# MM32F3270 register map
File version: 3.01
CPU: CM3 r2p1, selectable endian, MPU, no FPU, 3 interrupt priority bits
Registers are 32-bit, read-write, reset 0x0 unless marked. A register's access mark holds for its fields unless they carry their own. Offsets are from the block's base; [hi:lo] are bit positions; {n}, {i} and the like mark numbered series.

## EXTI — External interrupt/event controller
Base 0x40010400
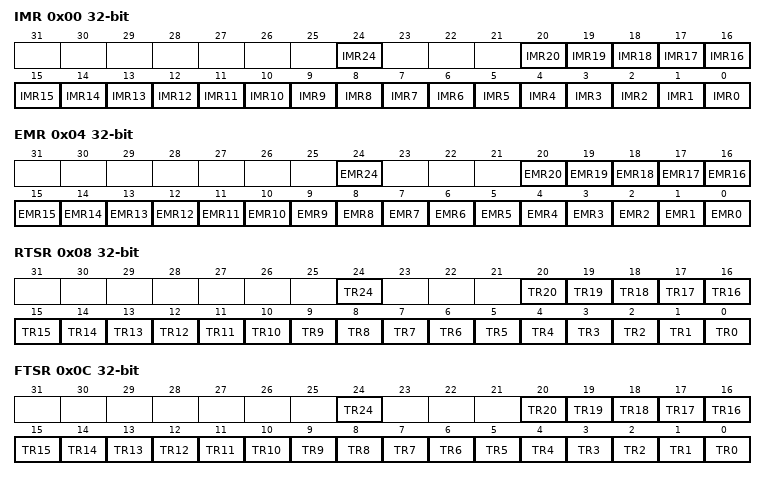
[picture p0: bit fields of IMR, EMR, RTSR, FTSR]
0x00 IMR — Interrupt mask register
  [24] IMR24 — Interrupt Mask on line 24
  [n] IMR{n} (n=0..20) — Interrupt Mask on line {n}
0x04 EMR — Event mask register
  [24] EMR24 — Event Mask on line 24
  [n] EMR{n} (n=0..20) — Event Mask on line {n}
0x08 RTSR — Rising trigger selection register
  [24] TR24 — Rising trigger event configuration bit of line 24
  [n] TR{n} (n=0..20) — Rising trigger event configuration bit of line {n}
0x0C FTSR — Falling trigger selection register
  [24] TR24 — Falling trigger event configuration bit of line 24
  [n] TR{n} (n=0..20) — Falling trigger event configuration bit of line {n}
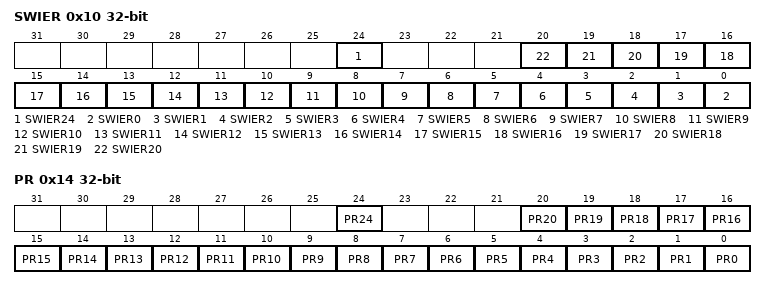
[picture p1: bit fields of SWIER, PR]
0x10 SWIER — Software interrupt event register
  [24] SWIER24 — Software interrupt on line 24
  [n] SWIER{n} (n=0..20) — Software interrupt on line {n}
0x14 PR write-1-clears — Pending register
  [24] PR24 — Pending bit
  [n] PR{n} (n=0..20) — Pending bit

## FLASH
Base 0x40022000
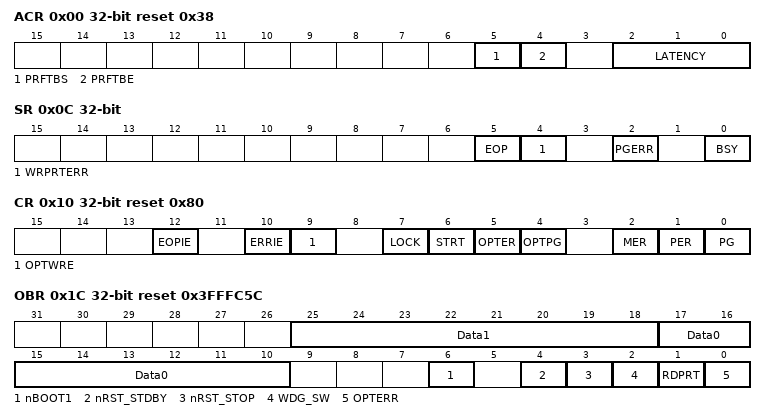
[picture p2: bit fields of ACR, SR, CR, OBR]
0x00 ACR reset 0x38 — Flash access control register
  [5] PRFTBS ro — Prefetch buffer status
  [4] PRFTBE — Prefetch enable
  [2:0] LATENCY
0x04 KEYR wo — Flash key
  [31:0] FKEYR
0x08 OPTKEYR wo — Option byte key
0x0C SR — Flash status register
  [5] EOP write-1-clears — End of operation
  [4] WRPRTERR write-1-clears — Write protection error
  [2] PGERR write-1-clears — Programming error
  [0] BSY ro — Busy
0x10 CR reset 0x80 — Flash control register
  [12] EOPIE — End of operation interrupt enable
  [10] ERRIE — Error interrupt enable
  [9] OPTWRE write-0-clears — Option byte write enable
  [7] LOCK
  [6] STRT — Start
  [5] OPTER — Option byte erase
  [4] OPTPG — Option byte programming
  [2] MER — Mass erase
  [1] PER — Page erase
  [0] PG — Programming
0x14 AR wo — Flash address register
  [31:0] FAR — Flash Address
0x1C OBR ro reset 0x3FFFC5C — Option byte register
  [25:18] Data1
  [17:10] Data0
  [6] nBOOT1
  [4] nRST_STDBY — Standby mode reset
  [3] nRST_STOP — Stop mode reset
  [2] WDG_SW — WDG selection
  [1] RDPRT — Read protection level status
  [0] OPTERR — Option byte error
{0x1C+4i} WRPR{i} ro reset 0xFFFFFFFF (i=1..4) — Write protect register
  [31:0] WRP — Write protect

## GPIOA — General purpose I/O
Base 0x40040000
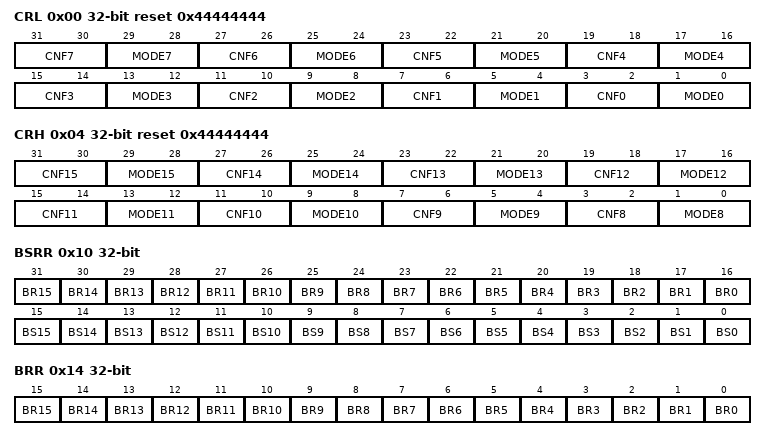
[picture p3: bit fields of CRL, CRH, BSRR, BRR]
0x00 CRL reset 0x44444444 — configuration low register
  [4n+3:4n+2] CNF{n} (n=0..7) — Port {n} configuration bits
  [4n+1:4n] MODE{n} (n=0..7) — Port {n} mode bits
0x04 CRH reset 0x44444444 — configuration high register
  [4n-29:4n-30] CNF{n} (n=8..15) — Port {n} configuration bits
  [4n-31:4n-32] MODE{n} (n=8..15) — Port {n} mode bits
0x08 IDR ro — input data register
  [15:0] IDR — Port input data
0x0C ODR — output data register
  [15:0] ODR — Port output data
0x10 BSRR wo — bit set/reset register
  [n+16] BR{n} (n=0..15) — Port x Reset bit {n}
  [n] BS{n} (n=0..15) — Port x Set bit {n}
0x14 BRR wo — bit reset register
  [n] BR{n} (n=0..15) — Port x Reset bit {n}
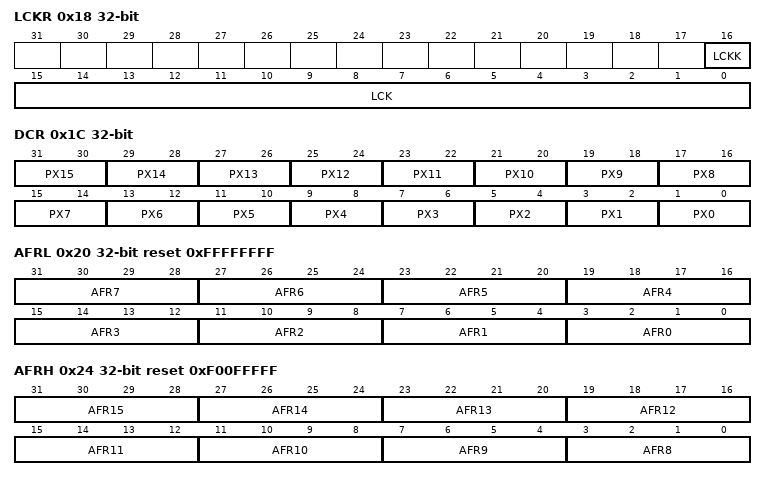
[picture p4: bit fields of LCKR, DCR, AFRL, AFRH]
0x18 LCKR — Port configuration lock register
  [16] LCKK — Lock key
  [15:0] LCK — Port x Lock bit y
0x1C DCR — Port output open drain control register
  [2n+1:2n] PX{n} (n=0..15)
0x20 AFRL reset 0xFFFFFFFF — Port Multiplexing Function Low Register
  [4n+3:4n] AFR{n} (n=0..7) — Multiplexing function selection for bit {n} of portx
0x24 AFRH reset 0xF00FFFFF — Port Multiplexing Function High Register
  [4n-29:4n-32] AFR{n} (n=8..15) — Multiplexing function selection for bit {n} of portx

## GPIOB — General purpose I/O
Base 0x40040400
Registers as GPIOA; these are added or differ:
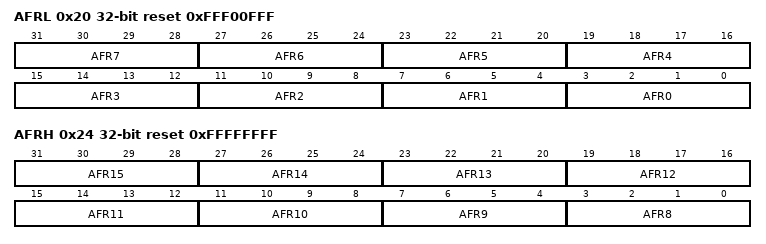
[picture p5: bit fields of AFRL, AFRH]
0x20 AFRL reset 0xFFF00FFF — Port Multiplexing Function Low Register
  [4n+3:4n] AFR{n} (n=0..7) — Multiplexing function selection for bit {n} of portx
0x24 AFRH reset 0xFFFFFFFF — Port Multiplexing Function High Register
  [4n-29:4n-32] AFR{n} (n=8..15) — Multiplexing function selection for bit {n} of portx

## GPIOC — General purpose I/O
Base 0x40040800
Same registers: GPIOD 0x40040C00, GPIOE 0x40041000, GPIOF 0x40041400, GPIOG 0x40041800, GPIOH 0x40041C00
Registers as GPIOB; these are added or differ:
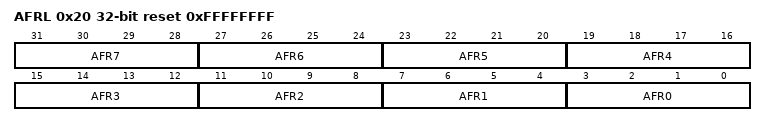
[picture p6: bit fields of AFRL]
0x20 AFRL reset 0xFFFFFFFF — Port Multiplexing Function Low Register
  [4n+3:4n] AFR{n} (n=0..7) — Multiplexing function selection for bit {n} of portx
